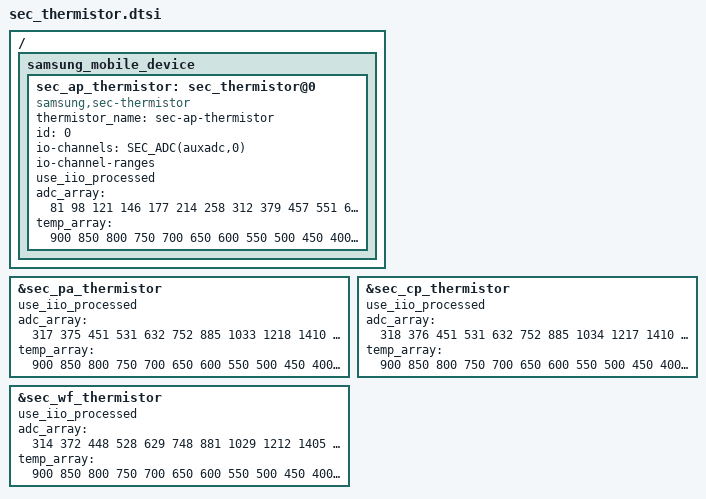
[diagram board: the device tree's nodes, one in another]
/ {
	fragment@smd {
		target-path = "/";
		__overlay__ {
			samsung_mobile_device {
				sec_ap_thermistor: sec_thermistor@0 {
					compatible = "samsung,sec-thermistor";
					status = "okay";
					thermistor_name = "sec-ap-thermistor";
					id = <0>;

					io-channels = SEC_ADC(auxadc,0);
					io-channel-names = "ap_therm";
					io-channel-ranges;
				};
			};
		};
	};
};

/* /home/dpi/qb5_8814/workspace/P4_1716/android/kernel/kmodule/hwmon/sec_thermistor/sec_thermistor_mtk.m53x.dtsi */
&sec_ap_thermistor {
	use_iio_processed;
	adc_array = <81 98 121 146 177 214 258 312 379 457
				551 684 843 1021 1214 1440 1705 1994 2259 2593
				2919 3245 3579>;

	temp_array = <900 850 800 750 700 650 600 550 500 450
				400 350 300 250 200 150 100 50 0 (-50)
				(-100) (-150) (-200)>;
};

&sec_pa_thermistor {
	use_iio_processed;
	adc_array = <317 375 451 531 632 752 885 1033 1218 1410
				1630 1906 2211 2492 2765 3043 3321 3579 3782 4004>;

	temp_array = <900 850 800 750 700 650 600 550 500 450
				400 350 300 250 200 150 100 50 0 (-50)>;
};

&sec_cp_thermistor {
	use_iio_processed;
	adc_array = <318 376 451 531 632 752 885 1034 1217 1410
				1628 1905 2215 2490 2763 3043 3319 3578 3782 4004>;

	temp_array = <900 850 800 750 700 650 600 550 500 450
				400 350 300 250 200 150 100 50 0 (-50)>;
};

&sec_wf_thermistor {
	use_iio_processed;
	adc_array = <314 372 448 528 629 748 881 1029 1212 1405
				1623 1899 2207 2484 2757 3037 3314 3573 3777 4000>;

	temp_array = <900 850 800 750 700 650 600 550 500 450
				400 350 300 250 200 150 100 50 0 (-50)>;
};
